# LPC176x5x register map
File version: 0.2
LPC176x/LPC175x M3
CPU: CM3 r0p0, little endian, MPU, no FPU, 5 interrupt priority bits
Registers are 32-bit, read-write, reset 0x0 unless marked. A register's access mark holds for its fields unless they carry their own. Offsets are from the block's base; lines under a group give offsets from that group; [hi:lo] are bit positions; {n}, {i} and the like mark numbered series; 'fields as' and 'values as' point back to an identical list; <NAME> marks a mode.

## Memory map
0x2009C000 GPIO size 0xFFF — General Purpose I/O

## GPIO — General Purpose I/O
Base 0x2009C000
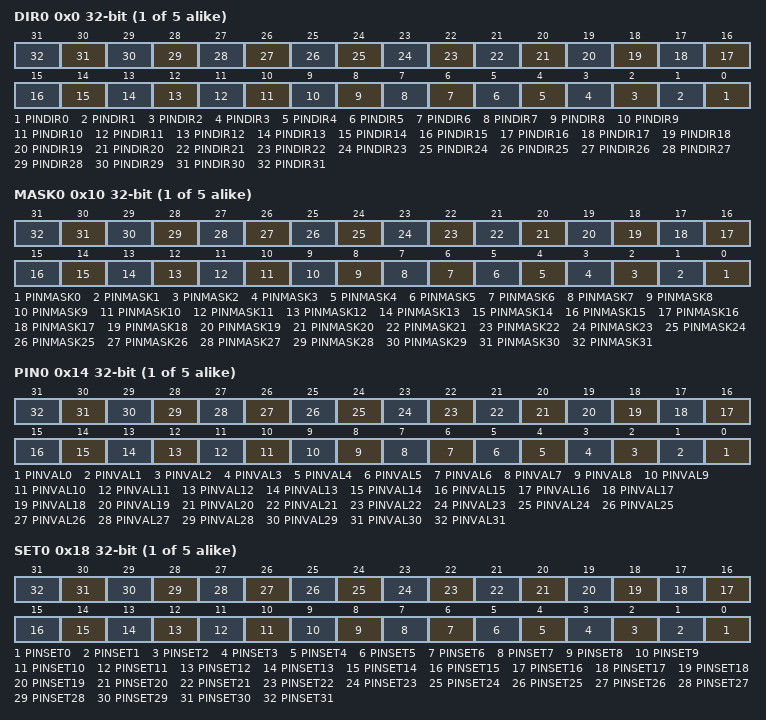
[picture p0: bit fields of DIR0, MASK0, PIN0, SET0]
{0x0+0x20*i} DIR{i} (i=0..4) — GPIO Port Direction control register.
  [n] PINDIR{n} (n=0..31) — Fast GPIO Direction PORTx control bits. Bit 0 in DIRx controls pin Px[0], bit 31 in DIRx controls pin Px[31]. 0 = Controlled pin is input. 1 = Controlled pin is output.
{0x10+0x20*i} MASK{i} (i=0..4) — Mask register for Port.
  [n] PINMASK{n} (n=0..31) — Fast GPIO physical pin access control. 0 = Controlled pin is affected by writes to the port's SETx, CLRx, and PINx register(s). Current state of the pin can be read from the PINx register. 1 = Controlled pin is not affected by writes into the port's SETx, CLRx and PINx register(s). When the PINx register is read, this bit will not be updated with the state of the physical pin.
{0x14+0x20*i} PIN{i} (i=0..4) — Port Pin value register using FIOMASK.
  [n] PINVAL{n} (n=0..31) — Fast GPIO output value Set bits. Bit 0 in PINx corresponds to pin Px[0], bit 31 in PINx corresponds to pin Px[31]. 0 = Controlled pin output is set to LOW. 1 = Controlled pin output is set to HIGH.
{0x18+0x20*i} SET{i} (i=0..4) — Port Output Set register using FIOMASK.
  [n] PINSET{n} (n=0..31) — Fast GPIO output value Set bits. Bit 0 in SETx controls pin Px[0], bit 31 in SETx controls pin Px[31]. 0 = Controlled pin output is unchanged. 1 = Controlled pin output is set to HIGH.
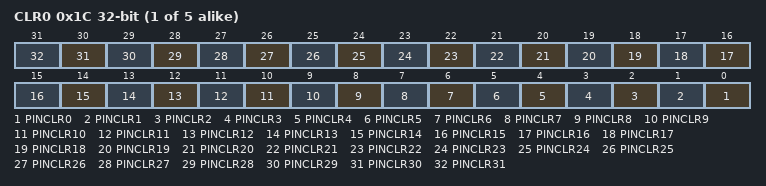
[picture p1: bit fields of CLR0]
{0x1C+0x20*i} CLR{i} (i=0..4) wo — Port Output Clear register using FIOMASK.
  [n] PINCLR{n} (n=0..31) — Fast GPIO output value Clear bits. Bit 0 in CLRx controls pin Px[0], bit 31 in CLRx controls pin Px[31]. 0 = Controlled pin output is unchanged. 1 = Controlled pin output is set to LOW.
